# STM32H723VEH6 register map
File version: 1.0
Registers are 32-bit, access not given, reset 0x0 unless marked. A register's access mark holds for its fields unless they carry their own. Offsets are from the block's base; [hi:lo] are bit positions; {n}, {i} and the like mark numbered series; 'fields as' and 'values as' point back to an identical list.

## LPUART1
Base 0x58000C00
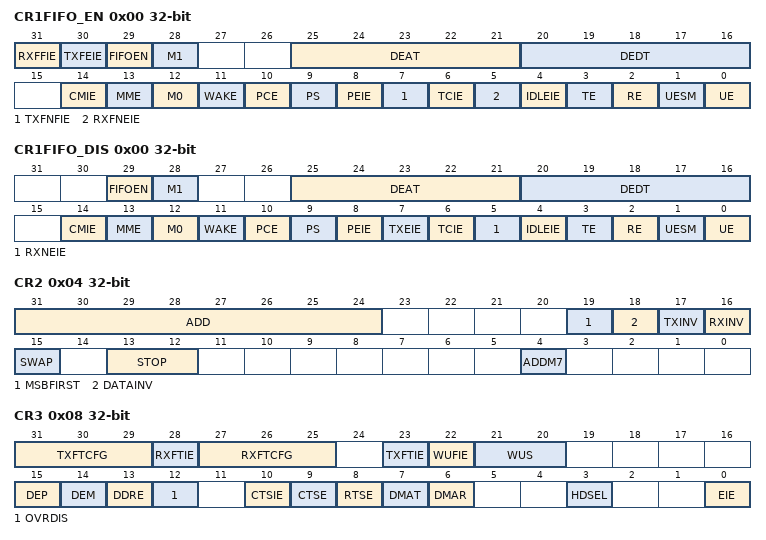
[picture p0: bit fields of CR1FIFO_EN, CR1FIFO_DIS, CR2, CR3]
0x00 CR1FIFO_EN
  [31] RXFFIE, [30] TXFEIE, [29] FIFOEN, [28] M1, [25:21] DEAT, [20:16] DEDT, [14] CMIE, [13] MME, [12] M0, [11] WAKE, [10] PCE, [9] PS, [8] PEIE, [7] TXFNFIE, [6] TCIE, [5] RXFNEIE, [4] IDLEIE, [3] TE, [2] RE, [1] UESM, [0] UE
0x00 CR1FIFO_DIS
  [29] FIFOEN, [28] M1, [25:21] DEAT, [20:16] DEDT, [14] CMIE, [13] MME, [12] M0, [11] WAKE, [10] PCE, [9] PS, [8] PEIE, [7] TXEIE, [6] TCIE, [5] RXNEIE, [4] IDLEIE, [3] TE, [2] RE, [1] UESM, [0] UE
0x04 CR2
  [31:24] ADD, [19] MSBFIRST, [18] DATAINV, [17] TXINV, [16] RXINV, [15] SWAP, [13:12] STOP, [4] ADDM7
0x08 CR3
  [31:29] TXFTCFG, [28] RXFTIE, [27:25] RXFTCFG, [23] TXFTIE, [22] WUFIE, [21:20] WUS, [15] DEP, [14] DEM, [13] DDRE, [12] OVRDIS, [10] CTSIE, [9] CTSE, [8] RTSE, [7] DMAT, [6] DMAR, [3] HDSEL, [0] EIE
0x0C BRR
  [19:0] BRR
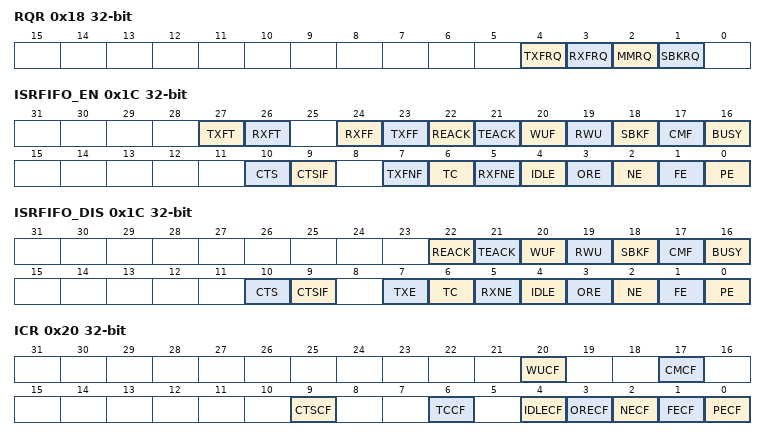
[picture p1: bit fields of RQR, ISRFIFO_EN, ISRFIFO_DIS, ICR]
0x18 RQR
  [4] TXFRQ, [3] RXFRQ, [2] MMRQ, [1] SBKRQ
0x1C ISRFIFO_EN
  [27] TXFT, [26] RXFT, [24] RXFF, [23] TXFF, [22] REACK, [21] TEACK, [20] WUF, [19] RWU, [18] SBKF, [17] CMF, [16] BUSY, [10] CTS, [9] CTSIF, [7] TXFNF, [6] TC, [5] RXFNE, [4] IDLE, [3] ORE, [2] NE, [1] FE, [0] PE
0x1C ISRFIFO_DIS
  [22] REACK, [21] TEACK, [20] WUF, [19] RWU, [18] SBKF, [17] CMF, [16] BUSY, [10] CTS, [9] CTSIF, [7] TXE, [6] TC, [5] RXNE, [4] IDLE, [3] ORE, [2] NE, [1] FE, [0] PE
0x20 ICR
  [20] WUCF, [17] CMCF, [9] CTSCF, [6] TCCF, [4] IDLECF, [3] ORECF, [2] NECF, [1] FECF, [0] PECF
0x24 RDR
  [8:0] RDR
0x28 TDR
  [8:0] TDR
0x2C PRESC
  [3:0] PRESCALER

## COMP2
Base 0x58003800
Same registers: COMP1 0x58003800
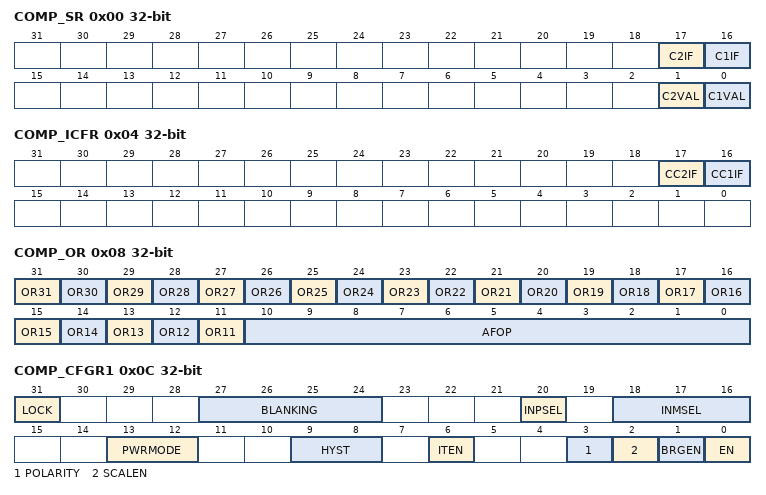
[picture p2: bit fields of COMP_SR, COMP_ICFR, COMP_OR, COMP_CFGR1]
0x00 COMP_SR
  [17] C2IF, [16] C1IF, [1] C2VAL, [0] C1VAL
0x04 COMP_ICFR
  [17] CC2IF, [16] CC1IF
0x08 COMP_OR
  [n] OR{n} (n=11..31), [10:0] AFOP
0x0C COMP_CFGR1
  [31] LOCK, [27:24] BLANKING, [20] INPSEL, [18:16] INMSEL, [13:12] PWRMODE, [9:8] HYST, [6] ITEN, [3] POLARITY, [2] SCALEN, [1] BRGEN, [0] EN
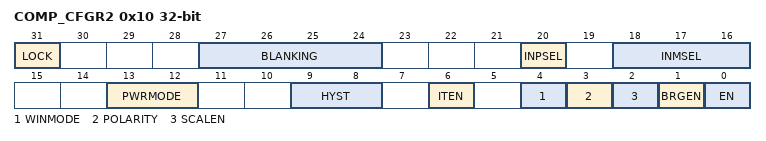
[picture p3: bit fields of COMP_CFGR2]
0x10 COMP_CFGR2
  [31] LOCK, [27:24] BLANKING, [20] INPSEL, [18:16] INMSEL, [13:12] PWRMODE, [9:8] HYST, [6] ITEN, [4] WINMODE, [3] POLARITY, [2] SCALEN, [1] BRGEN, [0] EN

## VREFBUF
Base 0x58003C00
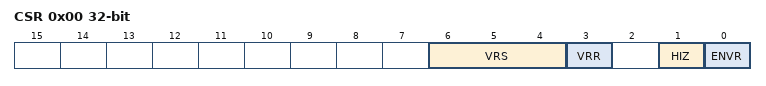
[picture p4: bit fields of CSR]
0x00 CSR
  [6:4] VRS, [3] VRR, [1] HIZ, [0] ENVR
0x04 CCR
  [5:0] TRIM

## RTC
Base 0x58004000
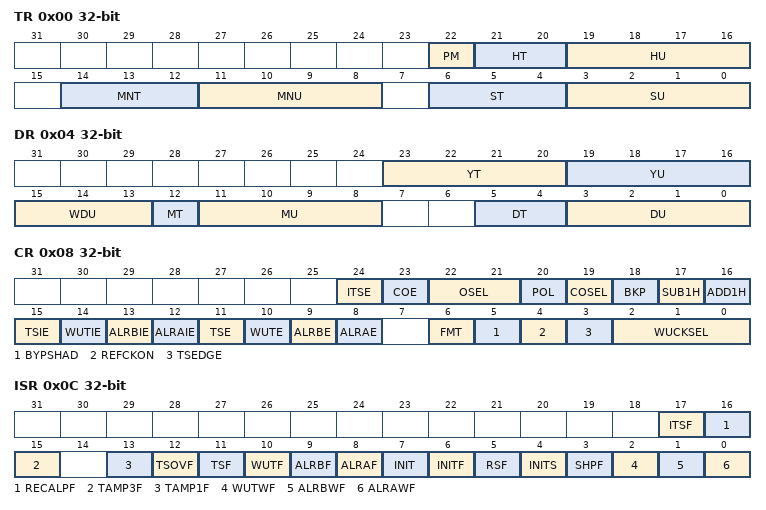
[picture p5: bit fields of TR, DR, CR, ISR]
0x00 TR
  [22] PM, [21:20] HT, [19:16] HU, [14:12] MNT, [11:8] MNU, [6:4] ST, [3:0] SU
0x04 DR
  [23:20] YT, [19:16] YU, [15:13] WDU, [12] MT, [11:8] MU, [5:4] DT, [3:0] DU
0x08 CR
  [24] ITSE, [23] COE, [22:21] OSEL, [20] POL, [19] COSEL, [18] BKP, [17] SUB1H, [16] ADD1H, [15] TSIE, [14] WUTIE, [13] ALRBIE, [12] ALRAIE, [11] TSE, [10] WUTE, [9] ALRBE, [8] ALRAE, [6] FMT, [5] BYPSHAD, [4] REFCKON, [3] TSEDGE, [2:0] WUCKSEL
0x0C ISR
  [17] ITSF, [16] RECALPF, [15] TAMP3F, [13] TAMP1F, [12] TSOVF, [11] TSF, [10] WUTF, [9] ALRBF, [8] ALRAF, [7] INIT, [6] INITF, [5] RSF, [4] INITS, [3] SHPF, [2] WUTWF, [1] ALRBWF, [0] ALRAWF
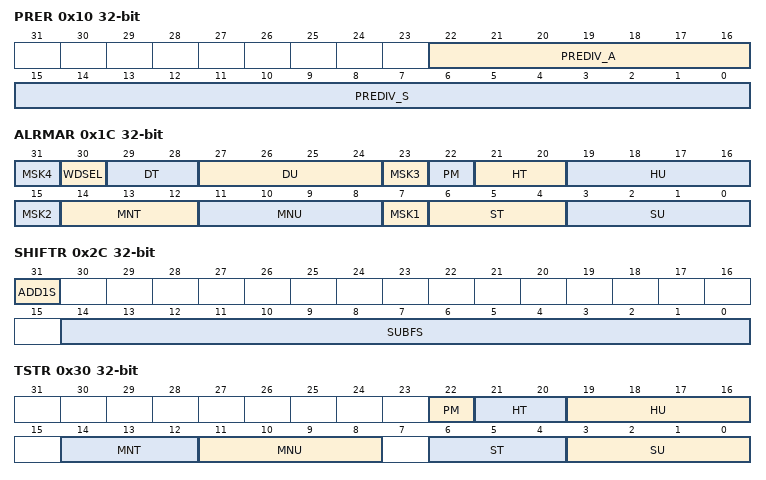
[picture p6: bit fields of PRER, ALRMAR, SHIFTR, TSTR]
0x10 PRER
  [22:16] PREDIV_A, [15:0] PREDIV_S
0x14 WUTR
  [15:0] WUT
0x1C ALRMAR
  [8n-1] MSK{n} (n=1..4), [30] WDSEL, [29:28] DT, [27:24] DU, [22] PM, [21:20] HT, [19:16] HU, [14:12] MNT, [11:8] MNU, [6:4] ST, [3:0] SU
0x20 ALRMBR
  [31] MSK4, [30] WDSEL, [29:28] DT, [27:24] DU, [23] MSK3, [22] PM, [21:20] HT, [19:16] HU, [14:12] MNT, [11:8] MNU, [15:7] MSK2, [6:4] ST, [3:0] SU
0x24 WPR
  [7:0] KEY
0x28 SSR
  [15:0] SS
0x2C SHIFTR
  [31] ADD1S, [14:0] SUBFS
0x30 TSTR
  fields as TR
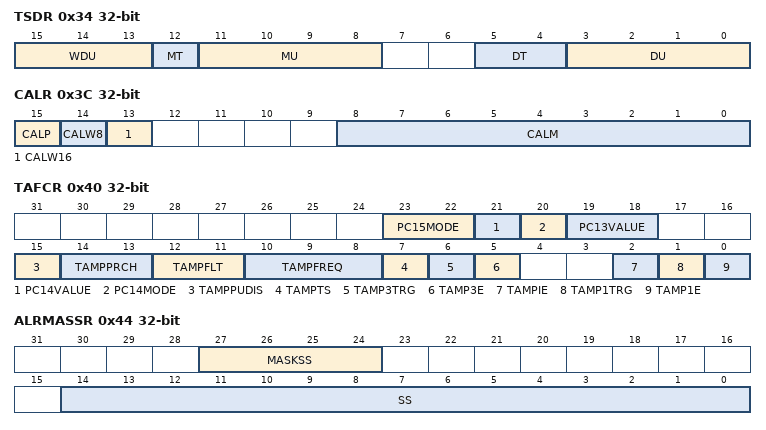
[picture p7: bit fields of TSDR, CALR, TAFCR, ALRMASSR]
0x34 TSDR
  [15:13] WDU, [12] MT, [11:8] MU, [5:4] DT, [3:0] DU
0x38 TSSSR
  [15:0] SS
0x3C CALR
  [15] CALP, [14] CALW8, [13] CALW16, [8:0] CALM
0x40 TAFCR
  [23:22] PC15MODE, [21] PC14VALUE, [20] PC14MODE, [19:18] PC13VALUE, [15] TAMPPUDIS, [14:13] TAMPPRCH, [12:11] TAMPFLT, [10:8] TAMPFREQ, [7] TAMPTS, [6] TAMP3TRG, [5] TAMP3E, [2] TAMPIE, [1] TAMP1TRG, [0] TAMP1E
0x44 ALRMASSR
  [27:24] MASKSS, [14:0] SS
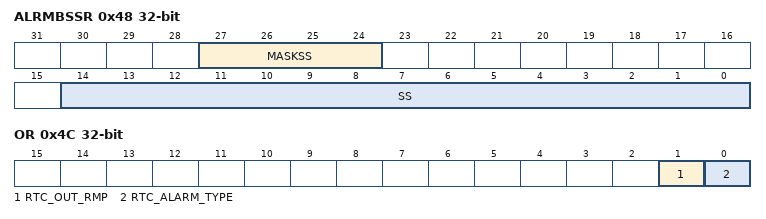
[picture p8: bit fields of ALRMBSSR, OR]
0x48 ALRMBSSR
  [27:24] MASKSS, [14:0] SS
0x4C OR
  [1] RTC_OUT_RMP, [0] RTC_ALARM_TYPE
{0x50+4i} BKP{i}R (i=0..31)
  [31:0] BKP

## BKP
Base 0x58004000
Registers as RTC; these are added or differ:
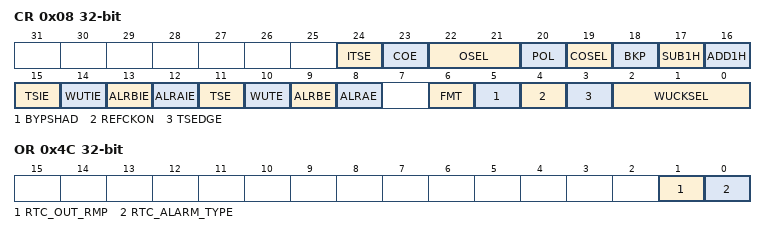
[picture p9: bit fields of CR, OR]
0x08 CR
  fields as RTC.CR
0x4C OR
  [1] RTC_OUT_RMP, [0] RTC_ALARM_TYPE
{0x50+4i} BKP{i}R (i=0..31)
  [31:0] BKP

## IWDG
Base 0x58004800
0x00 KR
  [15:0] KEY
0x04 PR
  [2:0] PR
0x08 RLR
  [11:0] RL
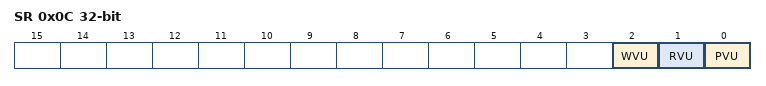
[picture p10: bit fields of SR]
0x0C SR
  [2] WVU, [1] RVU, [0] PVU
0x10 WINR
  [11:0] WIN

## DTS
Base 0x58006800
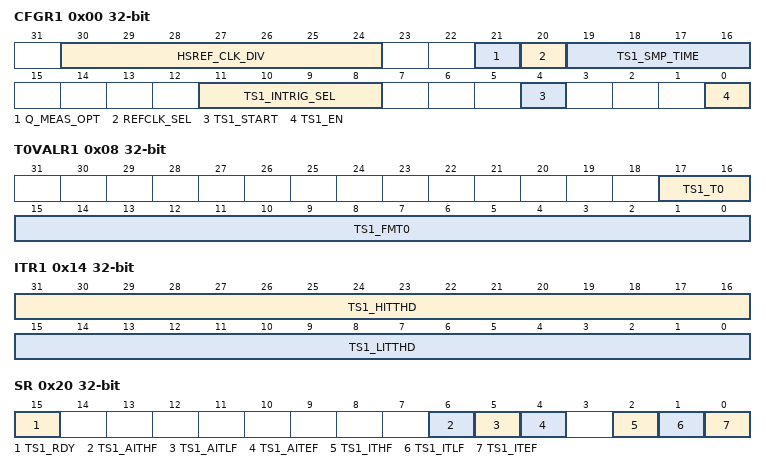
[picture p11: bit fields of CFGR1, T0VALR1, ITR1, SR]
0x00 CFGR1
  [30:24] HSREF_CLK_DIV, [21] Q_MEAS_OPT, [20] REFCLK_SEL, [19:16] TS1_SMP_TIME, [11:8] TS1_INTRIG_SEL, [4] TS1_START, [0] TS1_EN
0x08 T0VALR1
  [17:16] TS1_T0, [15:0] TS1_FMT0
0x10 RAMPVALR
  [15:0] TS1_RAMP_COEFF
0x14 ITR1
  [31:16] TS1_HITTHD, [15:0] TS1_LITTHD
0x1C DR
  [15:0] TS1_MFREQ
0x20 SR
  [15] TS1_RDY, [6] TS1_AITHF, [5] TS1_AITLF, [4] TS1_AITEF, [2] TS1_ITHF, [1] TS1_ITLF, [0] TS1_ITEF
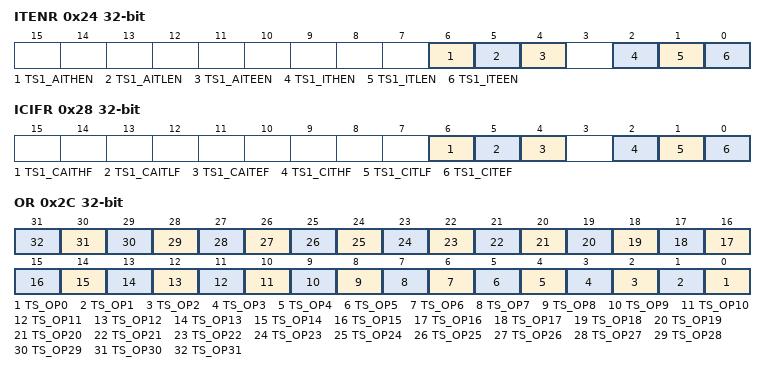
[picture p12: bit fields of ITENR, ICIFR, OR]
0x24 ITENR
  [6] TS1_AITHEN, [5] TS1_AITLEN, [4] TS1_AITEEN, [2] TS1_ITHEN, [1] TS1_ITLEN, [0] TS1_ITEEN
0x28 ICIFR
  [6] TS1_CAITHF, [5] TS1_CAITLF, [4] TS1_CAITEF, [2] TS1_CITHF, [1] TS1_CITLF, [0] TS1_CITEF
0x2C OR
  [n] TS_OP{n} (n=0..31)

## GPIOA
Base 0x58020000
Same registers: GPIOB 0x58020400, GPIOJ 0x58022400, GPIOK 0x58022800
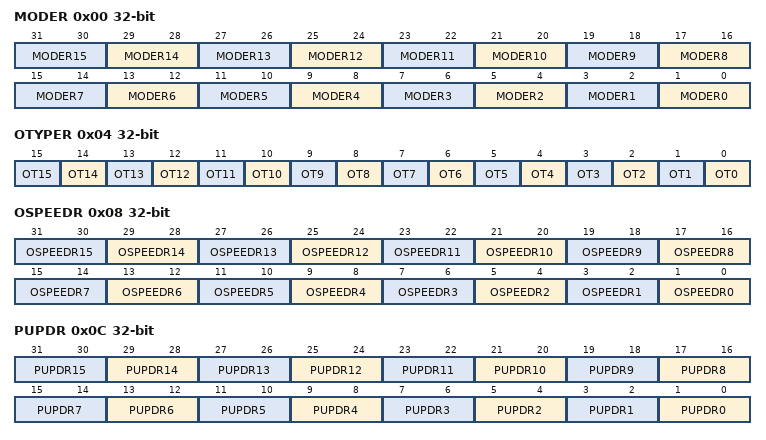
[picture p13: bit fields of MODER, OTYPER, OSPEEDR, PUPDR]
0x00 MODER
  [2n+1:2n] MODER{n} (n=0..15)
0x04 OTYPER
  [n] OT{n} (n=0..15)
0x08 OSPEEDR
  [2n+1:2n] OSPEEDR{n} (n=0..15)
0x0C PUPDR
  [2n+1:2n] PUPDR{n} (n=0..15)
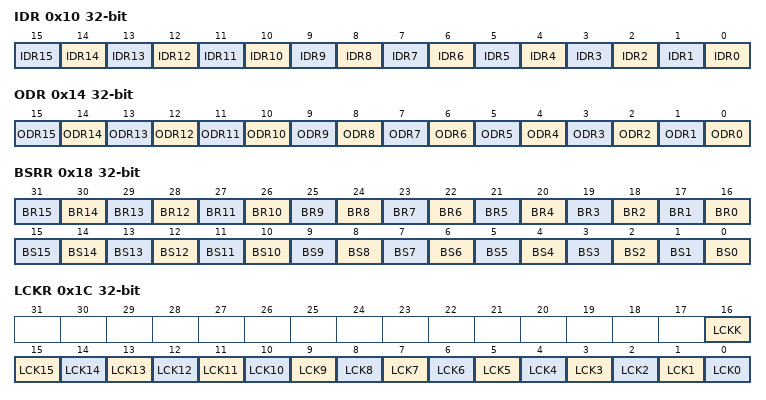
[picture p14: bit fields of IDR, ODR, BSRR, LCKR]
0x10 IDR
  [n] IDR{n} (n=0..15)
0x14 ODR
  [n] ODR{n} (n=0..15)
0x18 BSRR
  [n+16] BR{n} (n=0..15), [n] BS{n} (n=0..15)
0x1C LCKR
  [16] LCKK, [n] LCK{n} (n=0..15)
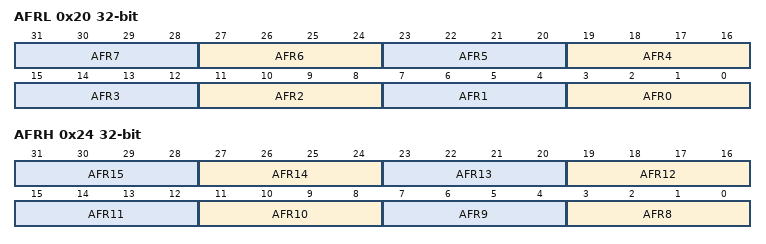
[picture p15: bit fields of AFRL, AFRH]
0x20 AFRL
  [4n+3:4n] AFR{n} (n=0..7)
0x24 AFRH
  [4n-29:4n-32] AFR{n} (n=8..15)

## GPIOC
Base 0x58020800
Same registers: GPIOD 0x58020C00, GPIOE 0x58021000, GPIOF 0x58021400, GPIOG 0x58021800, GPIOH 0x58021C00
Registers as GPIOA; these are added or differ:
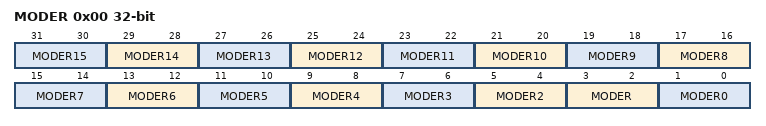
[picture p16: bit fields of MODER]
0x00 MODER
  [2n+1:2n] MODER{n} (n=2..15), [3:2] MODER, [1:0] MODER0

## PWR
Base 0x58024800
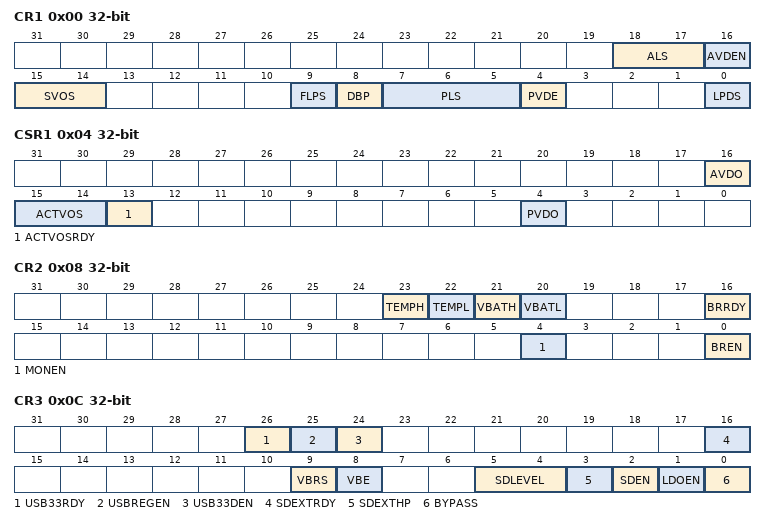
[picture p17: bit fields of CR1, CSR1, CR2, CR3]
0x00 CR1
  [18:17] ALS, [16] AVDEN, [15:14] SVOS, [9] FLPS, [8] DBP, [7:5] PLS, [4] PVDE, [0] LPDS
0x04 CSR1
  [16] AVDO, [15:14] ACTVOS, [13] ACTVOSRDY, [4] PVDO
0x08 CR2
  [23] TEMPH, [22] TEMPL, [21] VBATH, [20] VBATL, [16] BRRDY, [4] MONEN, [0] BREN
0x0C CR3
  [26] USB33RDY, [25] USBREGEN, [24] USB33DEN, [16] SDEXTRDY, [9] VBRS, [8] VBE, [5:4] SDLEVEL, [3] SDEXTHP, [2] SDEN, [1] LDOEN, [0] BYPASS
0x10 CPUCR
  [11] RUN_D3, [9] CSSF, [8] SBF_D2, [7] SBF_D1, [6] SBF, [5] STOPF, [2] PDDS_D3, [1] PDDS_D2, [0] PDDS_D1
0x18 D3CR
  [15:14] VOS, [13] VOSRDY
0x20 WKUPCR
  [5] WKUPC6, [3] WKUPC4, [1] WKUPC2, [0] WKUPC1
0x24 WKUPFR
  [5] WKUPF6, [3] WKUPF4, [1] WKUPF2, [0] WKUPF1
0x28 WKUPEPR
  [27:26] WKUPPUPD6, [23:22] WKUPPUPD4, [19:18] WKUPPUPD2, [17:16] WKUPPUPD1, [13] WKUPP6, [11] WKUPP4, [9] WKUPP2, [8] WKUPP1, [5] WKUPEN6, [3] WKUPEN4, [1] WKUPEN2, [0] WKUPEN1

## CRC
Base 0x58024C00
0x00 DR
0x04 IDR
0x08 CR
  [7] REV_OUT, [6:5] REV_IN, [4:3] POLYSIZE, [0] RESET
0x10 INIT
  [31:0] CRC_INIT
0x14 POL

## BDMA
Base 0x58025400
0x00 ISR
  [4n+3] TEIF{n} (n=0..7), [4n+2] HTIF{n} (n=0..7), [4n+1] TCIF{n} (n=0..7), [4n] GIF{n} (n=0..7)
0x04 IFCR
  [4n+3] CTEIF{n} (n=0..7), [4n+2] CHTIF{n} (n=0..7), [4n+1] CTCIF{n} (n=0..7), [4n] CGIF{n} (n=0..7)
{0x8+0x14*i} CCR{i} (i=0..7)
  [16] CT, [15] DBM, [14] MEM2MEM, [13:12] PL, [11:10] MSIZE, [9:8] PSIZE, [7] MINC, [6] PINC, [5] CIRC, [4] DIR, [3] TEIE, [2] HTIE, [1] TCIE, [0] EN
{0xC+0x14*i} CNDTR{i} (i=0..7)
  [15:0] NDTR
{0x10+0x14*i} CPAR{i} (i=0..7)
  [31:0] PA
{0x14+0x14*i} CM0AR{i} (i=0..7)
  [31:0] MA
{0x18+0x14*i} CM1AR{i} (i=0..7)
  [31:0] MA

## HSEM
Base 0x58026400
{0x0+4i} R{i} (i=0..31)
  [31] LOCK, [11:8] MASTERID, [7:0] PROCID
{0x80+4i} RLR{i} (i=0..31)
  [31] LOCK, [11:8] MASTERID, [7:0] PROCID
0x100 IER
  [31:0] ISE
0x104 ICR
  [31:0] ISC
0x108 ISR
  [31:0] ISF
0x10C MISR
  [31:0] MISF
0x140 CR
  [31:16] KEY, [11:8] MASTERID
0x144 KEYR
  [31:16] KEY
